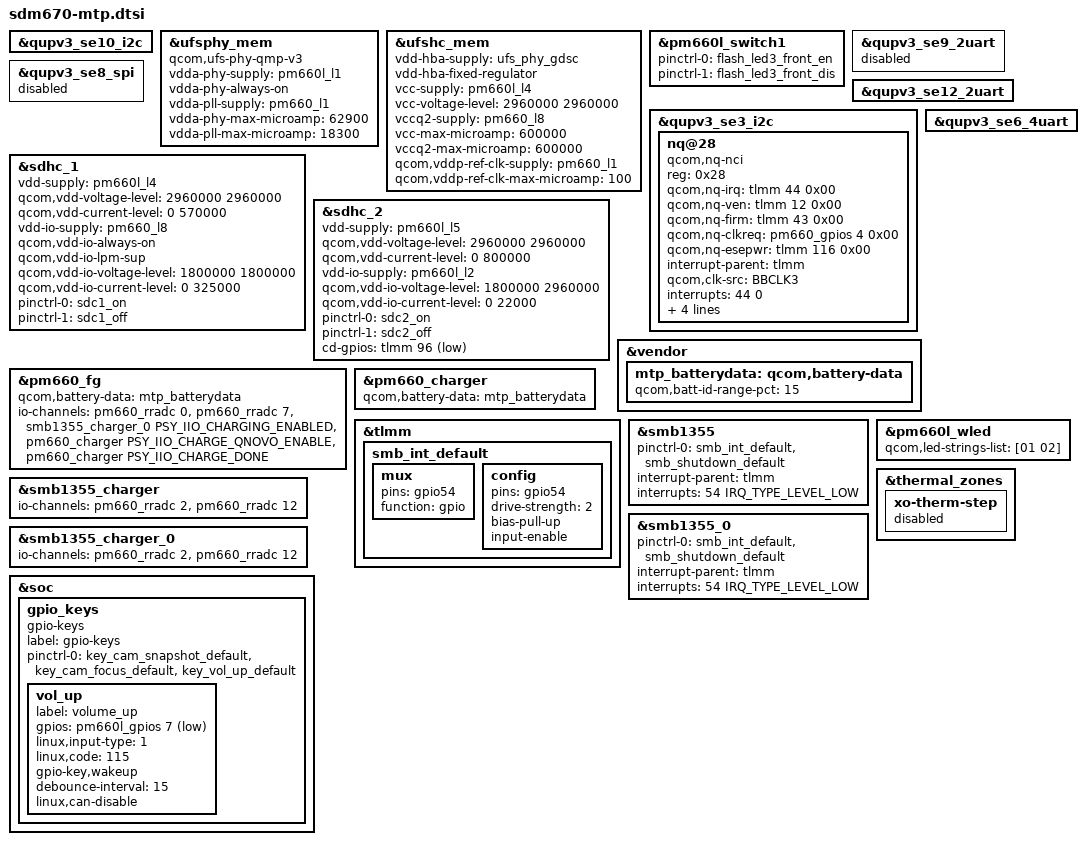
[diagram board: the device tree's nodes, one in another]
#include <dt-bindings/gpio/gpio.h>
#include "sdm670-pmic-overlay.dtsi"

&qupv3_se10_i2c {
#include "smb1355.dtsi"
};

&ufsphy_mem {
	compatible = "qcom,ufs-phy-qmp-v3";

	vdda-phy-supply = <&pm660l_l1>; /* 0.88v */
	vdda-phy-always-on;
	vdda-pll-supply = <&pm660_l1>; /* 1.2v */
	vdda-phy-max-microamp = <62900>;
	vdda-pll-max-microamp = <18300>;

	status = "ok";
};

&ufshc_mem {
	vdd-hba-supply = <&ufs_phy_gdsc>;
	vdd-hba-fixed-regulator;
	vcc-supply = <&pm660l_l4>;
	vcc-voltage-level = <2960000 2960000>;
	vccq2-supply = <&pm660_l8>;
	vcc-max-microamp = <600000>;
	vccq2-max-microamp = <600000>;

	qcom,vddp-ref-clk-supply = <&pm660_l1>;
	qcom,vddp-ref-clk-max-microamp = <100>;

	status = "ok";
};

&pm660l_switch1 {
	pinctrl-names = "led_enable", "led_disable";
	pinctrl-0 = <&flash_led3_front_en>;
	pinctrl-1 = <&flash_led3_front_dis>;
};

&qupv3_se9_2uart {
	status = "disabled";
};

&qupv3_se12_2uart {
	status = "ok";
};

&qupv3_se8_spi {
	status = "disabled";
};

&qupv3_se3_i2c {
	status = "ok";
	nq@28 {
		compatible = "qcom,nq-nci";
		reg = <0x28>;
		qcom,nq-irq = <&tlmm 44 0x00>;
		qcom,nq-ven = <&tlmm 12 0x00>;
		qcom,nq-firm = <&tlmm 43 0x00>;
		qcom,nq-clkreq = <&pm660_gpios 4 0x00>;
		qcom,nq-esepwr = <&tlmm 116 0x00>;
		interrupt-parent = <&tlmm>;
		qcom,clk-src = "BBCLK3";
		interrupts = <44 0>;
		interrupt-names = "nfc_irq";
		pinctrl-names = "nfc_active", "nfc_suspend";
		pinctrl-0 = <&nfc_int_active
			     &nfc_enable_active
			     &nfc_clk_default>;
		pinctrl-1 = <&nfc_int_suspend &nfc_enable_suspend>;
		clocks = <&rpmhcc RPMH_LN_BB_CLK3>;
		clock-names = "ref_clk";
	};
};

&qupv3_se10_i2c {
	status = "ok";
};

&qupv3_se6_4uart {
	status = "ok";
};

&sdhc_1 {
	vdd-supply = <&pm660l_l4>;
	qcom,vdd-voltage-level = <2960000 2960000>;
	qcom,vdd-current-level = <0 570000>;

	vdd-io-supply = <&pm660_l8>;
	qcom,vdd-io-always-on;
	qcom,vdd-io-lpm-sup;
	qcom,vdd-io-voltage-level = <1800000 1800000>;
	qcom,vdd-io-current-level = <0 325000>;

	pinctrl-names = "default", "sleep";
	pinctrl-0 = <&sdc1_on>;
	pinctrl-1 = <&sdc1_off>;

	status = "ok";
};

&sdhc_2 {
	vdd-supply = <&pm660l_l5>;
	qcom,vdd-voltage-level = <2960000 2960000>;
	qcom,vdd-current-level = <0 800000>;

	vdd-io-supply = <&pm660l_l2>;
	qcom,vdd-io-voltage-level = <1800000 2960000>;
	qcom,vdd-io-current-level = <0 22000>;

	pinctrl-names = "default", "sleep";
	pinctrl-0 = <&sdc2_on>;
	pinctrl-1 = <&sdc2_off>;

	cd-gpios = <&tlmm 96 0x1>;

	status = "ok";
};

&vendor {
	mtp_batterydata: qcom,battery-data {
		qcom,batt-id-range-pct = <15>;
		#include "fg-gen3-batterydata-itech-3000mah.dtsi"
		#include "fg-gen3-batterydata-ascent-3450mah.dtsi"
		#include "fg-gen3-batterydata-demo-6000mah.dtsi"
	};
};

&pm660_fg {
	qcom,battery-data = <&mtp_batterydata>;
	io-channels = <&pm660_rradc 0>,
		      <&pm660_rradc 7>,
		      <&smb1355_charger_0 PSY_IIO_CHARGING_ENABLED>,
		      <&pm660_charger PSY_IIO_CHARGE_QNOVO_ENABLE>,
		      <&pm660_charger PSY_IIO_CHARGE_DONE>;
	io-channel-names = "rradc_batt_id",
			   "rradc_die_temp",
			   "charging_enabled",
			   "charge_qnovo_enable",
			   "charge_done";
};

&pm660_charger {
	qcom,battery-data = <&mtp_batterydata>;
};

&tlmm {
	smb_int_default: smb_int_default {
		mux {
			pins = "gpio54";
			function = "gpio";
		};

		config {
			pins = "gpio54";
			drive-strength = <2>;
			bias-pull-up;
			input-enable;
		};
	};
};

&smb1355 {
	pinctrl-names = "default";
	pinctrl-0 = <&smb_int_default
			&smb_shutdown_default>;
	interrupt-parent = <&tlmm>;
	interrupts = <54 IRQ_TYPE_LEVEL_LOW>;
	status ="ok";

};

&smb1355_charger {
	#io-channel-cells = <1>;

	io-channels = <&pm660_rradc 2>,
			<&pm660_rradc 12>;
	io-channel-names = "charger_temp",
			"charger_temp_max";
	status ="ok";
};

&smb1355_0 {
	pinctrl-names = "default";
	pinctrl-0 = <&smb_int_default
			&smb_shutdown_default>;
	interrupt-parent = <&tlmm>;
	interrupts = <54 IRQ_TYPE_LEVEL_LOW>;
	status ="ok";

};

&smb1355_charger_0 {
	#io-channel-cells = <1>;

	io-channels = <&pm660_rradc 2>,
			<&pm660_rradc 12>;
	io-channel-names = "charger_temp",
			"charger_temp_max";
	status ="ok";
};

&soc {
	gpio_keys {
		compatible = "gpio-keys";
		label = "gpio-keys";

		pinctrl-names = "default";
		pinctrl-0 = <&key_cam_snapshot_default
			     &key_cam_focus_default
			     &key_vol_up_default>;

		vol_up {
			label = "volume_up";
			gpios = <&pm660l_gpios 7 GPIO_ACTIVE_LOW>;
			linux,input-type = <1>;
			linux,code = <115>;
			gpio-key,wakeup;
			debounce-interval = <15>;
			linux,can-disable;
		};
	};
};

&pm660l_wled {
	status = "okay";
	qcom,led-strings-list = [01 02];
};

&thermal_zones {
	xo-therm-step {
		status = "disabled";
	};
};
